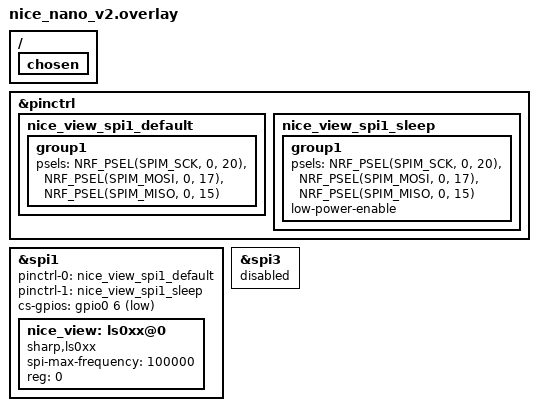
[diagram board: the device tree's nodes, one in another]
/* Custom nice_view adapter for hardwired pins:
 * SCK=P0.20, MOSI=P0.17, CS=P0.06 (active-low)
 */

&pinctrl {
	nice_view_spi1_default: nice_view_spi1_default {
		group1 {
			psels = <NRF_PSEL(SPIM_SCK, 0, 20)>,
				<NRF_PSEL(SPIM_MOSI, 0, 17)>,
				<NRF_PSEL(SPIM_MISO, 0, 15)>; /* dummy / not connected */
		};
	};

	nice_view_spi1_sleep: nice_view_spi1_sleep {
		group1 {
			psels = <NRF_PSEL(SPIM_SCK, 0, 20)>,
				<NRF_PSEL(SPIM_MOSI, 0, 17)>,
				<NRF_PSEL(SPIM_MISO, 0, 15)>;
			low-power-enable;
		};
	};
};

/* This label MUST exist for the nice_view shield overlay */
nice_view_spi: &spi1 {
	status = "okay";
	pinctrl-0 = <&nice_view_spi1_default>;
	pinctrl-1 = <&nice_view_spi1_sleep>;
	pinctrl-names = "default", "sleep";

	/* CS = P0.06 */
	cs-gpios = <&gpio0 6 GPIO_ACTIVE_LOW>;

	nice_view: ls0xx@0 {
		compatible = "sharp,ls0xx";
		spi-max-frequency = <100000>;
		reg = <0>;
	};
};

/* Kill underglow, which commonly claims P0.06 via SPI3 MOSI */
&spi3 {
	status = "disabled";
};

/ {
	chosen {
		/delete-property/ zmk,underglow;
	};
};
